# USBFSHOST register map
Vendor: Texas Instruments
Peripheral module from a debugger description file (folder omap4430).
Registers are 32-bit, access per field, reset 0x0 unless marked. A register's access mark holds for its fields unless they carry their own. Offsets are as the file gives them; lines under a group give offsets from that group; [hi:lo] are bit positions; {n}, {i} and the like mark numbered series; 'fields as' and 'values as' point back to an identical list; <NAME> marks a mode.

## USBFSHOST
0x00 HCREVISION ro reset not defined — OHCI revision number
  [31:0] RESERVED — IP Revision
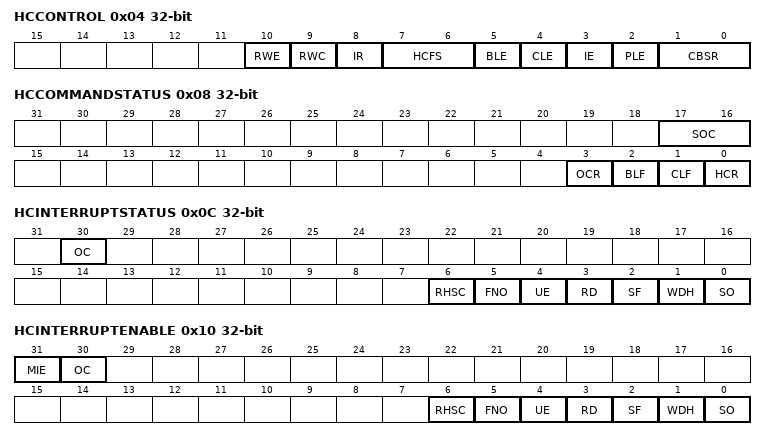
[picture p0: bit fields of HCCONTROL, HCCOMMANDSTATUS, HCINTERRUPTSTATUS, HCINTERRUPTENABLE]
0x04 HCCONTROL — HC operating mode register
  [10] RWE rw — Remote wake-up enable
  [9] RWC rw — Remote wake up connected.
  [8] IR rw — Interrupt routing.
  [7:6] HCFS rw — Host controller functional state
    0=HCFS: USB reset; 1=HCFS: USB resume; 2=HCFS: USB operational; 3=HCFS: USB suspend
  [5] BLE rw — Bulk list processing enable
    0=The bulk ED list is not processed after the next SOF; 1=Enables processing of the bulk ED list in the next frame
  [4] CLE rw — Control list processing enable
    0=Control ED list is not processed after the next SOF; 1=Enables processing of control ED list in the next frame
  [3] IE rw — Isochronous ED processing enabled by host controller driver.
    0=Isochronous EDs are not processed; 1=Enables processing of isochronous EDs
  [2] PLE rw — Periodic list enable
    0=Periodic ED lists are not processed after the next frame; 1=Enables processing of periodic ED lists in the next frame
  [1:0] CBSR rw — Control/bulk service ratio. Specifies the ratio between control and bulk EDs processedin a frame.
    0=One control ED per bulk ED; 1=Two control ED per bulk ED; 2=Three control ED per bulk ED; 3=Four control ED per bulk ED
0x08 HCCOMMANDSTATUS — HC Command and status
  [17:16] SOC ro — Scheduling overrun count
  [3] OCR rw — Ownership change request
  [2] BLF rw — Bulk list filled
  [1] CLF rw — Control list filled
  [0] HCR rw — Host controller reset (software reset)Set this bit to initiate a USB host controller reset. This resets most USB host controller OHCI registers. OHCI register accesses must not be attempted until a read of this register returns a 0.
    0=No effect; 1=USB host controller is reset
0x0C HCINTERRUPTSTATUS
  [30] OC ro — Ownership change
  [6] RHSC rw — Root hub status changeWhen 0x1: A root hub status change has occurred.Write 0x0: No effectWrite 0x1: Clears this bit
  [5] FNO rw — Frame number overflowWhen 0x1: A frame number overflow has occurred.Write 0x0: No effectWrite 0x1: Clears this bit
  [4] UE rw — Unrecoverable error.When 0x1: An unrecoverable error has occurred.Write 0x0: No effectWrite 0x1: Clears this bit
  [3] RD rw — Resume detected.When 0x1: A downstream device has issued a resume request.Write 0x0: No effectWrite 0x1: Clears this bit
  [2] SF rw — Start of frame.When 0x1: A SOF has been issued.Write 0x0: No effectWrite 0x1: Clears this bit
  [1] WDH rw — Write done headWhen 0x1: the USB host controller has updated the HCDONEHEAD register.Write 0x0: No effectWrite 0x1: Clears this bit
  [0] SO rw — Scheduling overrunWhen 0x1: A scheduling overrun has occurred.Write 0x0: No effectWrite 0x1: Clears this bit
0x10 HCINTERRUPTENABLE
  [31] MIE rw — Master interrupt enableWhen 0x1: Allows other enabled OHCI interrupt sources to propagate to the device interrupt controller.When 0x0: OHCI interrupt sources are ignored.Write 0x0: No effectWrite 0x1: Sets this bit
  [30] OC rw — Ownership change
  [6] RHSC rw — Root hub status changeWhen 0x1 and MIE is 0x1: Allows root hub status change interrupts to propagate to the device interrupt controller.When 0x0 or MIE is 0x0: root hub status change interrupts do not propagate.Write 0x0: No effectWrite 0x1: Sets this bit
  [5] FNO rw — Frame number overflow.When 0x1 and MIE is 0x1: Allows FNO interrupts to propagate to the device interrupt controller.When 0x0 or MIE is 0x0: FNO interrupts do not propagate.Write 0x0: No effectWrite 0x1: Sets this bit
  [4] UE rw — Unrecoverable error.When 0x1 and MIE is 0x1: Allows UE interrupts to propagate to the device interrupt controller.When 0x0 or MIE is 0x0: UE interrupts do not propagate.Write 0x0: No effectWrite 0x1: Sets this bit
  [3] RD rw — Resume detected.When 0x1 and MIE is 0x1: Allows RD interrupts to propagate to the device interrupt controller.When 0x0 or MIE is 0x0: RD interrupts do not propagate.Write 0x0: No effectWrite 0x1: Sets this bit
  [2] SF rw — Start of frameWhen 0x1 and MIE is 0x1: Allows SF interrupts to propagate to the device interrupt controller.When 0x0 or MIE is 0x0: SF interrupts do not propagate.Write 0x0: No effectWrite 0x1: Sets this bit
  [1] WDH rw — Write done headWhen 0x1 and MIE is 0x1: Allows WDH interrupts to propagate to the device interrupt controller.When 0x0 or MIE is 0x0: WDH interrupts do not propagate.Write 0x0: No effectWrite 0x1: Sets this bit
  [0] SO rw — Scheduling overrun.When 0x1 and MIE is 0x1: Allows SO interrupts to propagate to the device interrupt controller.When 0x0 or MIE is 0x0: SO interrupts do not propagate.Write 0x0: No effectWrite 0x1: Sets this bit
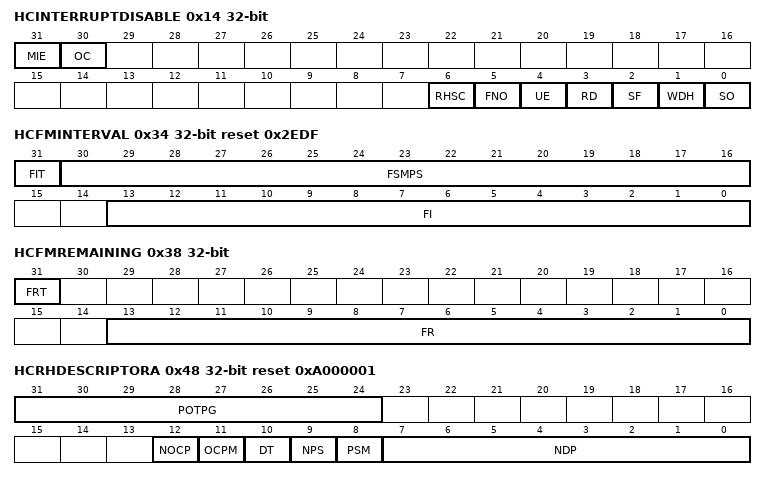
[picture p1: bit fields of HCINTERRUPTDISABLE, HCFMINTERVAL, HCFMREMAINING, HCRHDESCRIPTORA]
0x14 HCINTERRUPTDISABLE
  [31] MIE rw — Master interrupt enableAlways reads 0x0Write 0x0: No effectWrite 0x1: Clears the HCINTERRUPTENABLE MIE bit
  [30] OC rw — Ownership change
  [6] RHSC rw — Root hub status changeAlways reads 0x0Write 0x0: No effectWrite 0x1: Clears the HCINTERRUPTENABLE RHSC bit
  [5] FNO rw — Frame number overflowAlways reads 0x0Write 0x0: No effectWrite 0x1: Clears the HCINTERRUPTENABLE FNO bit
  [4] UE rw — Unrecoverable errorAlways reads 0x0Write 0x0: No effectWrite 0x1: Clears the HCINTERRUPTENABLE UE bit
  [3] RD rw — Resume detectedAlways reads 0x0Write 0x0: No effectWrite 0x1: Clears the HCINTERRUPTENABLE RD bit
  [2] SF rw — Start of frameAlways reads 0x0Write 0x0: No effectWrite 0x1: Clears the HCINTERRUPTENABLE SF bit
  [1] WDH rw — Write done headAlways reads 0x0Write 0x0: No effectWrite 0x1: Clears the HCINTERRUPTENABLE WDH bit
  [0] SO rw — Scheduling overrunAlways reads 0x0Write 0x0: No effectWrite 0x1: Clears the HCINTERRUPTENABLE SO bit
0x18 HCHCCA — HC HCCA address register
  [31:8] HCCA rw — Physical address of the beginning of the HCCA
0x1C HCPERIODCURRENTED ro — HC Current periodic register
  [31:4] PCED — Physical address of current ED on the periodic ED list
0x20 HCCONTROLHEADED — HC head control register
  [31:4] CHED rw — Physical address of head ED on the control ED list
0x24 HCCONTROLCURRENTED — HC current control register
  [31:4] CCED rw — Physical address of current ED on the control ED list
0x28 HCBULKHEADED — HC head bulk register
  [31:4] BHED rw — Physical address of head ED on the bulk ED list
0x2C HCBULKCURRENTED — HC current bulk register
  [31:4] BCED rw — Physical address of current ED on the bulk ED list
0x30 HCDONEHEAD ro — HC head done register
  [31:4] DH — Physical address of last TD that was added to the done queue
0x34 HCFMINTERVAL reset 0x2EDF — HC Frame Interval register
  [31] FIT rw — Frame interval toggle
  [30:16] FSMPS rw — Largest data packet size for full-speed packets, bit times.
  [13:0] FI rw — Frame intervalNumber of 12-MHz clocks in the USB frame. The nominal value is set to 11,999 to give a 1-ms frame.
0x38 HCFMREMAINING ro — HC Frame-remaining register
  [31] FRT — Frame remaining toggle
  [13:0] FR — Frame remaining
0x3C HCFMNUMBER ro — HC Frame number register
  [15:0] FN — Frame number
0x40 HCPERIODICSTART
  [13:0] PS rw — Periodic startThe host controller driver must program this value to be about 10% less than the frame interval field value so that control and bulk EDs have priority for the first 10% of the frame; then periodic EDs have priority for the remaining 90% of the frame.
0x44 HCLSTHRESHOLD reset 0x628 — HC low-speed threshold register
  [11:0] LST rw — Low-speed threshold.
0x48 HCRHDESCRIPTORA reset 0xA000001 — HC root hub A register
  [31:24] POTPG rw — Power-on to power-good timeDefines the minimum length of time (2 ms * POTPG) between the USB host controller turning on power to a downstream port, and when the USB host can access the downstream device.
  [12] NOCP rw — No overcurrent protection
    0=Overcurrent status is reported collectively for all downstream ports; 1=the USB host controller does not implement overcurrent protection inputs
  [11] OCPM rw — Overcurrent protection mode
  [10] DT ro — Device typeAlways reads 0x0: Indicates that the USB host controller implemented is not a compound device
  [9] NPS rw — No power switching
    0=VBUS power switching is supported, either per-port or all-port switched per the power; 1=VBUS power switching is not supported, power is available to all downstream ports
  [8] PSM rw — Power switching mode
    0=Indicates that all ports are powered at the same time; 1=Individual port power switching is supported
  [7:0] NDP ro — Number of downstream ports.
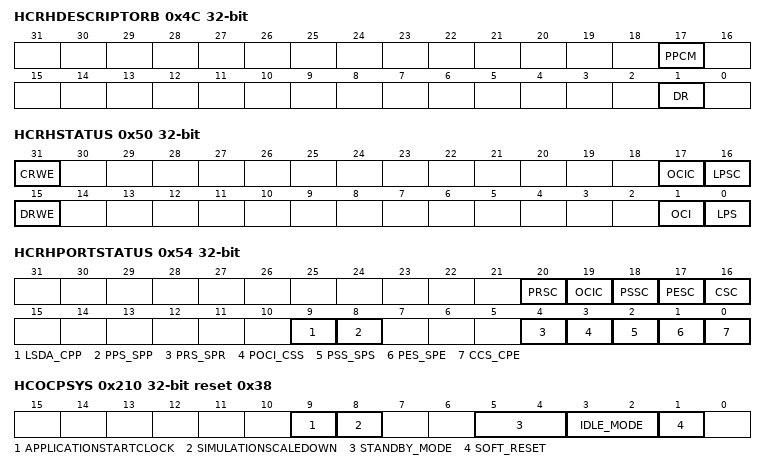
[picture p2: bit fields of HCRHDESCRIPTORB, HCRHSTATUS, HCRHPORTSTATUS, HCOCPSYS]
0x4C HCRHDESCRIPTORB — HC root hub B register
  [17] PPCM rw — Port power control maskThis bit defines whether downstream port #1 has port power controlled by the global power control. When set. the port power state is only affected by per-port power control. When cleared the port is controlled by the global power switch. This field is not valid if the device is configured to global switch mode.
  [1] DR rw — Device removableThis bit defines whether the downstream port has a removable device. When cleared, the attached device is removable. When set, the attached device is not removable. bit 1: Device attached to port #1
0x50 HCRHSTATUS — HC root hub status register
  [31] CRWE wo — Clear remote wake-up enableWrite 0x0: No effectWrite 0x1: Clears the device remote wake-up enable bit
  [17] OCIC rw — Overcurrent indication changeThis bit is automatically set when the overcurrent indicator bit changes.Write 0x0: No effectWrite 0x1: Clears this bit
  [16] LPSC rw — Local power status changeAlways reads 0x0: The root hub does not support the local power status feature.Write 0x0: No effectWrite 0x1: Sets port power status bits for all ports, if power switching mode is 0. Sets port power status bits for ports with their corresponding port power control mask bits cleared if power switching mode is 1.
  [15] DRWE rw — Device remote wake-up enableEnables a connect status change event as a resume event, causing a USB suspend to USB resume state transition and sets the resume detected interrupt status bit.Read 0x1: Connect status change is a remote wake-up event.Read 0x0: Connect status change is not a remote wake-up event.Write 0x0: No effectWrite 0x1: Sets the device remote wake-up enable bit
  [1] OCI ro — Overcurrent indicator. Reports global overcurrent indication if global overcurrent reporting is selected. If per-port overcurrent protection is implemented, this bit is always 0.
    0=OCI_0_r (All power operations are normal.); 1=OCI_1_r (An overcurrent condition exists.)
  [0] LPS rw — Local power status.Always reads 0x0Write 0x0: No effectWrite 0x1: When in global power mode (power switching mode = 0), turns off power to all ports. If in per-port power mode (power switching mode = 1), turns of power to those ports whose corresponding port power control mask bit is 0.
0x54 HCRHPORTSTATUS — HC Port 1 status and control register
  [20] PRSC rw — Port 1 reset status changeThis bit is set when the Port 1 port reset status bit has changed.Write 0x0: No effectWrite 0x1: Clears this bit
  [19] OCIC rw — Port 1 overcurrent indicator changeThis bit is set when the Port 1 port overcurrent indicator has changed.Write 0x0: No effectWrite 0x1: Clears this bit
  [18] PSSC rw — Port 1 suspend status changeThis bit is set when the Port1 port suspend status has changed.Write 0x0: No effectWrite 0x1: Clears this bit
  [17] PESC rw — Port 1 enable status changeThis bit is set when the Port1 port enable status has changed.Write 0x0: No effectWrite 0x1: Clears this bit
  [16] CSC rw — Port 1 connect status changeThis bit is set when the Port1 port current connect status has changed due to a connect or disconnect event. If current connect status is 0 when a set port reset, set port enable, or set port suspend write occurs, this bit is set.Write 0x0: No effectWrite 0x1: Clears this bitNote: If the DR bit HCRHDESCRIPTORB[1] is set, this bit is set only after a root hub reset to inform the system that the device is attached.
  [9] LSDA_CPP rw — Port 1 low-speed device attached/clear port power. This bit is valid only when port 1 current connect status is 1.Read 0x0: A full-speed device is attached to port 1.Read 0x1: A low-speed device is attached to port 1.Write 0x0: No effectWrite 0x1: Clears the port 1 port power status.
  [8] PPS_SPP rw — Port 1 port power status/set port power.Read 0x0: Port 1 power is off.Read 0x1: Port 1 power is on.Write 0x0: No effectWrite 0x1: Sets the port 1 port power status bit
  [4] PRS_SPR rw — Port 1 port reset status/set port reset.Read 0x0: USB reset is not being sent to port 1.Read 0x1: Port 1 is signaling the USB reset.Write 0x0: No effectWrite 0x1: Sets the port 1 port reset status bit and causes the USB host controller to begin signaling USB reset to port 1
  [3] POCI_CSS rw — Port 1 port overcurrent indicator/clear suspend statusRead 0x0: No port 1 port overcurrent condition has occurred.Read 0x1: A port 1 port overcurrent condition has occurred.Write 0x0: No effectWrite 0x1: When port 1 port suspend status is 1, it causes resume signaling on port 1. When port 1 port suspend status is 0, it has no effect.
  [2] PSS_SPS rw — Port 1 port suspend status/set port suspendThis bit is cleared automatically at the end of the USB resume sequence and also at the end of the USB reset sequence.Write 0x0: No effectRead 0x0: Port 1 is not in the USB suspend state.Read 0x1: Port 1 is in the USB suspend state or is in the resume sequence.Write 0x1: If port 1 current connect status is 1, sets the port 1 port suspend status bit and places port 1 in USB suspend state. If current connect status is 0, it sets connect status instead change to inform the USB host controller driver in an attempt to suspend a disconnected port.
  [1] PES_SPE rw — Port 1 port enable status/set port enableThis bit is automatically set at completion of port 1 USB reset, if it was not already set before the USB reset completed, and is automatically set at the end of a USB suspend, if the port was not enabled when the USB resume completed.Read 0x0: Port 1 is not enabled.Read 0x1: Port 1 is enabled.Write 0x0: No effectWrite 0x1: When port 1 current connect status is 1, sets the port 1 port enable status bit. When port 1 current status is 0, it has no effect.
  [0] CCS_CPE rw — Port 1 current connection status/clear port enableRead 0x0: No USB device is attached to port 1.Read 0x1: Port 1 currently has a USB device attached.Write 0x0: No effectWrite 0x1: Clears the port 1 port enable bitNote: This bit is set to 1 if the DR bit HCRHDESCRIPTORB[1] is set to indicate a nonremovable device on port 1.
0x200 HCOCPREV ro reset not defined
  [31:0] REVISION — IP Revision
0x204 HCOCPHWI ro reset 0x2A — Hardware information register, maintains the IP modules hardware configuration. The fields can be set to different values through parameters.
  [31:0] INFO — IP-module dependent. Information about the IP module hardware configuration, that is, typically the module HDL generics (if any).
0x210 HCOCPSYS reset 0x38 — OCP system configuration register holds the OCP power down control fields that controls the clock management.
  [9] APPLICATIONSTARTCLOCK rw — 1: RCFG_SUSPEND_O output port is masked and this output port is held low (1'b0)0: RCFG_SUSPEND_O port functions normally, that is, it indicates the SUSPEND mode.
  [8] SIMULATIONSCALEDOWN rw — 1: Simulation runs in time scaled down mode.0: Simulation runs in real time. NOTE: This bit should not be set to 1 in actual hardware.
  [5:4] STANDBY_MODE rw — Standby mode, controls the way USBFSHOST handles the STANDBY protocol.The application can program this field in the following configurations 2'b00 : Force standby 2'b01: Not supported (No-Standby) 2'b10: Smart standby 2'b11: Smart standby wake up
  [3:2] IDLE_MODE rw — The idle mode controls the way USBFSHOST handles the IDLE protocol.The application can program this field in the following configurations 2'b00: Force Idle 2'b01: Not supported (No-Idle) 2'b10: Smart-Idle 2'b11: Smart-Idle wake up
  [1] SOFT_RESET rw — Setting this bit to 1 resets the entire IP, except for OCP-IDLE, OCP-STANDBY, and OCP-DISCONNECT logic.This bit remains set until the IP comes out of soft reset.
